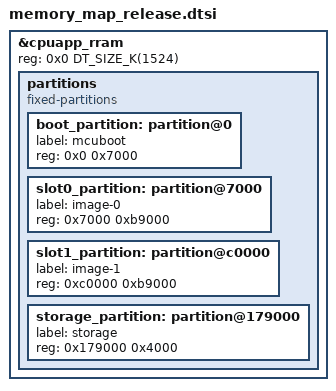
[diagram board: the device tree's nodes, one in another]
/*
 * Copyright (c) 2026 Nordic Semiconductor ASA
 *
 * SPDX-License-Identifier: LicenseRef-Nordic-5-Clause
 */

/* Application does not use cpuflpr core. Assign whole RRAM to cpuapp. */
&cpuapp_rram {
	reg = <0x0 DT_SIZE_K(1524)>;
};

&cpuapp_rram {
	/delete-node/ partitions;

	partitions {
		compatible = "fixed-partitions";
		#address-cells = <1>;
		#size-cells = <1>;

		boot_partition: partition@0 {
			label = "mcuboot";
			reg = <0x0 0x7000>;
		};

		slot0_partition: partition@7000 {
			label = "image-0";
			reg = <0x7000 0xb9000>;
		};

		slot1_partition: partition@c0000 {
			label = "image-1";
			reg = <0xc0000 0xb9000>;
		};

		storage_partition: partition@179000 {
			label = "storage";
			reg = <0x179000 0x4000>;
		};
	};
};
